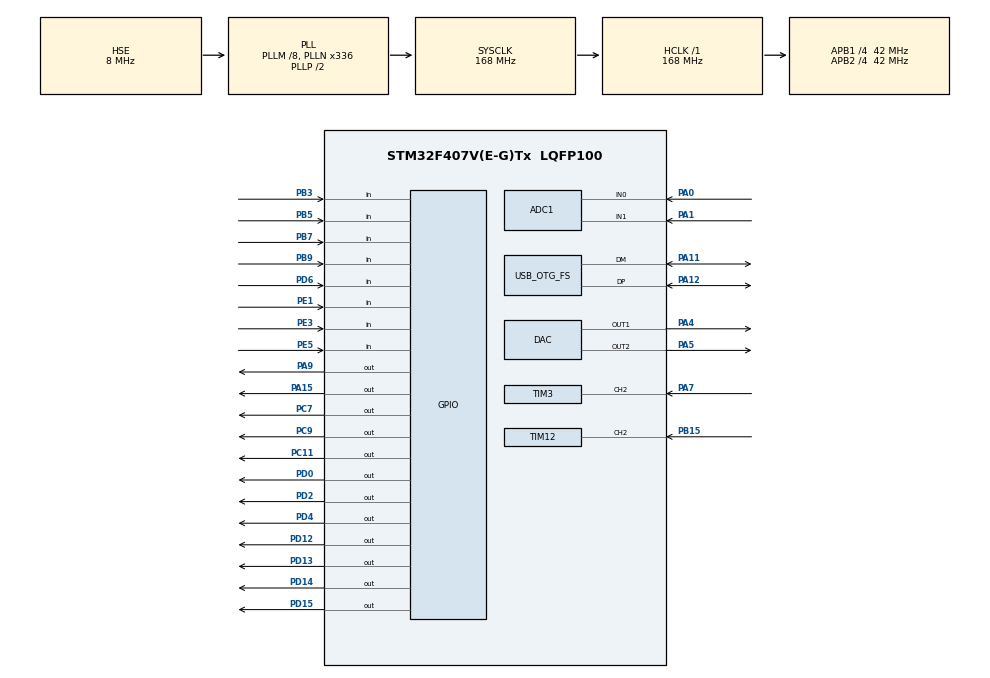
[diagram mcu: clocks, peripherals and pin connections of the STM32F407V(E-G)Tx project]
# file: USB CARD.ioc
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ADC1.AutoInjectedConv=DISABLE
ADC1.Channel-0\#ChannelRegularConversion=ADC_CHANNEL_0
ADC1.Channel-1\#ChannelRegularConversion=ADC_CHANNEL_1
ADC1.ContinuousConvMode=ENABLE
ADC1.DMAContinuousRequests=ENABLE
ADC1.EOCSelection=ADC_EOC_SEQ_CONV
ADC1.InjNumberOfConversion=0
ADC1.InjectedDiscontinuousConvMode=DISABLE
ADC1.NbrOfConversion=2
ADC1.NbrOfConversionFlag=1
ADC1.Rank-0\#ChannelRegularConversion=1
ADC1.Rank-1\#ChannelRegularConversion=2
ADC1.SamplingTime-0\#ChannelRegularConversion=ADC_SAMPLETIME_480CYCLES
ADC1.SamplingTime-1\#ChannelRegularConversion=ADC_SAMPLETIME_480CYCLES
ADC1.ScanConvMode=ENABLE
ADC1.master=1
DAC.DAC_Channel=DAC_CHANNEL_1
DAC.DAC_Channel2=DAC_CHANNEL_2
DAC.WaveGeneration=DISABLE
DAC.WaveGeneration2=DISABLE
Dma.ADC1.0.Direction=DMA_PERIPH_TO_MEMORY
Dma.ADC1.0.FIFOMode=DMA_FIFOMODE_DISABLE
Dma.ADC1.0.Instance=DMA2_Stream0
Dma.ADC1.0.MemDataAlignment=DMA_MDATAALIGN_HALFWORD
Dma.ADC1.0.MemInc=DMA_MINC_ENABLE
Dma.ADC1.0.Mode=DMA_CIRCULAR
Dma.ADC1.0.PeriphDataAlignment=DMA_PDATAALIGN_HALFWORD
Dma.ADC1.0.PeriphInc=DMA_PINC_DISABLE
Dma.ADC1.0.Priority=DMA_PRIORITY_LOW
Dma.Request0=ADC1
Mcu.Family=STM32F4
Mcu.Name=STM32F407V(E-G)Tx
Mcu.Package=LQFP100
NVIC.ADC_IRQn=true\:0\:0\:false\:false\:true
NVIC.DMA2_Stream0_IRQn=true\:0\:0\:false\:false\:true
NVIC.OTG_FS_IRQn=true\:0\:0\:false\:false\:true
NVIC.PriorityGroup=NVIC_PRIORITYGROUP_4
NVIC.TIM2_IRQn=true\:0\:0\:false\:false\:true
NVIC.TIM3_IRQn=true\:0\:0\:false\:false\:true
NVIC.TIM8_BRK_TIM12_IRQn=true\:0\:0\:false\:false\:true
PA0-WKUP.Signal=ADCx_IN0
PA1.Signal=ADCx_IN1
PA11.Mode=Device_Only
PA11.Signal=USB_OTG_FS_DM
PA12.Mode=Device_Only
PA12.Signal=USB_OTG_FS_DP
PA15.GPIO_ModeDefaultOutputPP=GPIO_MODE_OUTPUT_PP
PA15.GPIO_PuPd=GPIO_NOPULL
PA15.GPIO_Speed=GPIO_SPEED_FREQ_HIGH
PA15.PinState=GPIO_PIN_RESET
PA15.Signal=GPIO_Output
PA4.Signal=COMP_DAC1_group
PA5.Signal=COMP_DAC2_group
PA7.GPIO_PuPd=GPIO_PULLDOWN
PA7.GPIO_Speed=GPIO_SPEED_FREQ_HIGH
PA7.Signal=S_TIM3_CH2
PA9.GPIO_ModeDefaultOutputPP=GPIO_MODE_OUTPUT_PP
PA9.GPIO_PuPd=GPIO_NOPULL
PA9.GPIO_Speed=GPIO_SPEED_FREQ_HIGH
PA9.PinState=GPIO_PIN_RESET
PA9.Signal=GPIO_Output
PB15.GPIO_PuPd=GPIO_PULLDOWN
PB15.GPIO_Speed=GPIO_SPEED_FREQ_HIGH
PB15.Signal=S_TIM12_CH2
PB3.GPIO_Mode=GPIO_MODE_INPUT
PB3.GPIO_PuPd=GPIO_PULLUP
PB3.Signal=GPIO_Input
PB5.GPIO_Mode=GPIO_MODE_INPUT
PB5.GPIO_PuPd=GPIO_PULLUP
PB5.Signal=GPIO_Input
PB7.GPIO_Mode=GPIO_MODE_INPUT
PB7.GPIO_PuPd=GPIO_PULLUP
PB7.Signal=GPIO_Input
PB9.GPIO_Mode=GPIO_MODE_INPUT
PB9.GPIO_PuPd=GPIO_PULLUP
PB9.Signal=GPIO_Input
PC11.GPIO_ModeDefaultOutputPP=GPIO_MODE_OUTPUT_PP
PC11.GPIO_PuPd=GPIO_NOPULL
PC11.GPIO_Speed=GPIO_SPEED_FREQ_HIGH
PC11.PinState=GPIO_PIN_RESET
PC11.Signal=GPIO_Output
PC7.GPIO_ModeDefaultOutputPP=GPIO_MODE_OUTPUT_PP
PC7.GPIO_PuPd=GPIO_NOPULL
PC7.GPIO_Speed=GPIO_SPEED_FREQ_HIGH
PC7.PinState=GPIO_PIN_RESET
PC7.Signal=GPIO_Output
PC9.GPIO_ModeDefaultOutputPP=GPIO_MODE_OUTPUT_PP
PC9.GPIO_PuPd=GPIO_NOPULL
PC9.GPIO_Speed=GPIO_SPEED_FREQ_HIGH
PC9.PinState=GPIO_PIN_RESET
PC9.Signal=GPIO_Output
PD0.GPIO_ModeDefaultOutputPP=GPIO_MODE_OUTPUT_PP
PD0.GPIO_PuPd=GPIO_NOPULL
PD0.GPIO_Speed=GPIO_SPEED_FREQ_HIGH
PD0.PinState=GPIO_PIN_RESET
PD0.Signal=GPIO_Output
PD12.GPIO_ModeDefaultOutputPP=GPIO_MODE_OUTPUT_PP
PD12.GPIO_PuPd=GPIO_NOPULL
PD12.GPIO_Speed=GPIO_SPEED_FREQ_HIGH
PD12.PinState=GPIO_PIN_RESET
PD12.Signal=GPIO_Output
PD13.GPIO_ModeDefaultOutputPP=GPIO_MODE_OUTPUT_PP
PD13.GPIO_PuPd=GPIO_NOPULL
PD13.GPIO_Speed=GPIO_SPEED_FREQ_HIGH
PD13.PinState=GPIO_PIN_RESET
PD13.Signal=GPIO_Output
PD14.GPIO_ModeDefaultOutputPP=GPIO_MODE_OUTPUT_PP
PD14.GPIO_PuPd=GPIO_NOPULL
PD14.GPIO_Speed=GPIO_SPEED_FREQ_HIGH
PD14.PinState=GPIO_PIN_RESET
PD14.Signal=GPIO_Output
PD15.GPIO_ModeDefaultOutputPP=GPIO_MODE_OUTPUT_PP
PD15.GPIO_PuPd=GPIO_NOPULL
PD15.GPIO_Speed=GPIO_SPEED_FREQ_HIGH
PD15.PinState=GPIO_PIN_RESET
PD15.Signal=GPIO_Output
PD2.GPIO_ModeDefaultOutputPP=GPIO_MODE_OUTPUT_PP
PD2.GPIO_PuPd=GPIO_NOPULL
PD2.GPIO_Speed=GPIO_SPEED_FREQ_HIGH
PD2.PinState=GPIO_PIN_RESET
PD2.Signal=GPIO_Output
PD4.GPIO_ModeDefaultOutputPP=GPIO_MODE_OUTPUT_PP
PD4.GPIO_PuPd=GPIO_NOPULL
PD4.GPIO_Speed=GPIO_SPEED_FREQ_HIGH
PD4.PinState=GPIO_PIN_RESET
PD4.Signal=GPIO_Output
PD6.GPIO_Mode=GPIO_MODE_INPUT
PD6.GPIO_PuPd=GPIO_PULLUP
PD6.Signal=GPIO_Input
PE1.GPIO_Mode=GPIO_MODE_INPUT
PE1.GPIO_PuPd=GPIO_PULLUP
PE1.Signal=GPIO_Input
PE3.GPIO_Mode=GPIO_MODE_INPUT
PE3.GPIO_PuPd=GPIO_PULLUP
PE3.Signal=GPIO_Input
PE5.GPIO_Mode=GPIO_MODE_INPUT
PE5.GPIO_PuPd=GPIO_PULLUP
PE5.Signal=GPIO_Input
PH0-OSC_IN.Mode=HSE-External-Oscillator
PH0-OSC_IN.Signal=RCC_OSC_IN
PH1-OSC_OUT.Mode=HSE-External-Oscillator
PH1-OSC_OUT.Signal=RCC_OSC_OUT
ProjectManager.HeapSize=0x200
ProjectManager.StackSize=0x400
ProjectManager.TargetToolchain=MDK-ARM V5
RCC.48MHZClocksFreq_Value=48000000
RCC.AHBFreq_Value=168000000
RCC.APB1CLKDivider=RCC_HCLK_DIV4
RCC.APB1Freq_Value=42000000
RCC.APB1TimFreq_Value=84000000
RCC.APB2CLKDivider=RCC_HCLK_DIV4
RCC.APB2Freq_Value=42000000
RCC.APB2TimFreq_Value=84000000
RCC.ClockTypeHCLK=RCC_CLOCKTYPE_HCLK
RCC.ClockTypePCLK1=RCC_CLOCKTYPE_PCLK1
RCC.ClockTypePCLK2=RCC_CLOCKTYPE_PCLK2
RCC.ClockTypeSysClk=RCC_CLOCKTYPE_SYSCLK
RCC.CortexFreq_Value=168000000
RCC.EnableExtClockForI2S=false
RCC.EnableHSE=true
RCC.EnableHSERTCDevisor=false
RCC.EnableLSE=false
RCC.EnableLSERTC=false
RCC.ExtClockEnable=false
RCC.HCLKFreq_Value=168000000
RCC.HSEState=RCC_HSE_ON
RCC.HSE_VALUE=8000000
RCC.HSIState=RCC_HSI_OFF
RCC.HSI_VALUE=16000000
RCC.I2SEnable=false
RCC.IWDGEnable=false
RCC.LSE_VALUE=32768
RCC.LSIState=RCC_LSI_OFF
RCC.MCO1OutPutEnable=false
RCC.MCO2OutPutEnable=false
RCC.OscillatorTypeHSE=RCC_OSCILLATORTYPE_HSE
RCC.OscillatorTypeHSI=RCC_OSCILLATORTYPE_HSI
RCC.PLLM=8
RCC.PLLN=336
RCC.PLLQ=7
RCC.PLLSource=RCC_PLLSOURCE_HSE
RCC.PLLSourceVirtual=RCC_PLLSOURCE_HSE
RCC.PLLState=RCC_PLL_ON
RCC.RNGEnable=false
RCC.RTCEnable=false
RCC.SDIOEnable=false
RCC.SYSCLKFreq_VALUE=168000000
RCC.SYSCLKSource=RCC_SYSCLKSOURCE_PLLCLK
RCC.USBFSEnable=true
RCC.USBHSEnable=false
RCC.VCOOutputFreq_Value=336000000
SH.ADCx_IN0.0=ADC1_IN0,IN0
SH.ADCx_IN1.0=ADC1_IN1,IN1
SH.COMP_DAC1_group.0=DAC_OUT1,DAC_OUT1
SH.COMP_DAC2_group.0=DAC_OUT2,DAC_OUT2
SH.S_TIM12_CH2.0=TIM12_CH2,TriggerSource_TI2FP2
SH.S_TIM3_CH2.0=TIM3_CH2,TriggerSource_TI2FP2
TIM12.Period=65535
TIM12.Slave_TriggerFilter=15
TIM2.Period=499
TIM2.Prescaler=42000
TIM3.Period=65535
TIM3.Slave_TriggerFilter=15
USB_DEVICE.CLASS_NAME_FS=CUSTOMHID
USB_DEVICE.INTERFACE_STRING_CUSTOMHID_FS=USB Custom HID Interface
USB_DEVICE.MANUFACTURER_STRING-CUSTOM_HID_FS=DHBK - minht57
USB_DEVICE.PID_CUSTOMHID_FS=1996
USB_DEVICE.PRODUCT_STRING_CUSTOMHID_FS=USB CARD - minht57
USB_DEVICE.USBD_CUSTOMHID_OUTREPORT_BUF_SIZE-CUSTOM_HID_FS=64
USB_DEVICE.USBD_CUSTOM_HID_REPORT_DESC_SIZE-CUSTOM_HID_FS=64
USB_DEVICE.USBD_HandleTypeDef_FS=hUsbDevice_OTG_FS
USB_DEVICE.VID-CUSTOM_HID_FS=1010
USB_DEVICE.VirtualModeFS=Custom_Hid_FS
USB_OTG_FS.VirtualMode=Device_Only
USB_OTG_FS.dev_endpoints=4
USB_OTG_FS.phy_itface=PCD_PHY_EMBEDDED
VP_TIM12_VS_ControllerModeClock.Mode=Clock Mode
VP_TIM2_VS_ClockSourceINT.Mode=Internal
VP_TIM3_VS_ControllerModeClock.Mode=Clock Mode
VP_USB_DEVICE_VS_USB_DEVICE_CUSTOM_HID_FS.Mode=CUSTOM_HID_FS
board=USB CARD

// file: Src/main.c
/**
  ******************************************************************************
  * File Name          : main.c
  * Description        : Main program body
  ******************************************************************************
  *
  * Copyright (c) 2017 STMicroelectronics International N.V.
  * All rights reserved.
  *
  * Redistribution and use in source and binary forms, with or without
  * modification, are permitted, provided that the following conditions are met:
  *
  * 1. Redistribution of source code must retain the above copyright notice,
  *    this list of conditions and the following disclaimer.
  * 2. Redistributions in binary form must reproduce the above copyright notice,
  *    this list of conditions and the following disclaimer in the documentation
  *    and/or other materials provided with the distribution.
  * 3. Neither the name of STMicroelectronics nor the names of other
  *    contributors to this software may be used to endorse or promote products
  *    derived from this software without specific written permission.
  * 4. This software, including modifications and/or derivative works of this
  *    software, must execute solely and exclusively on microcontroller or
  *    microprocessor devices manufactured by or for STMicroelectronics.
  * 5. Redistribution and use of this software other than as permitted under
  *    this license is void and will automatically terminate your rights under
  *    this license.
  *
  * THIS SOFTWARE IS PROVIDED BY STMICROELECTRONICS AND CONTRIBUTORS "AS IS"
  * AND ANY EXPRESS, IMPLIED OR STATUTORY WARRANTIES, INCLUDING, BUT NOT
  * LIMITED TO, THE IMPLIED WARRANTIES OF MERCHANTABILITY, FITNESS FOR A
  * PARTICULAR PURPOSE AND NON-INFRINGEMENT OF THIRD PARTY INTELLECTUAL PROPERTY
  * RIGHTS ARE DISCLAIMED TO THE FULLEST EXTENT PERMITTED BY LAW. IN NO EVENT
  * SHALL STMICROELECTRONICS OR CONTRIBUTORS BE LIABLE FOR ANY DIRECT, INDIRECT,
  * INCIDENTAL, SPECIAL, EXEMPLARY, OR CONSEQUENTIAL DAMAGES (INCLUDING, BUT NOT
  * LIMITED TO, PROCUREMENT OF SUBSTITUTE GOODS OR SERVICES; LOSS OF USE, DATA,
  * OR PROFITS; OR BUSINESS INTERRUPTION) HOWEVER CAUSED AND ON ANY THEORY OF
  * LIABILITY, WHETHER IN CONTRACT, STRICT LIABILITY, OR TORT (INCLUDING
  * NEGLIGENCE OR OTHERWISE) ARISING IN ANY WAY OUT OF THE USE OF THIS SOFTWARE,
  * EVEN IF ADVISED OF THE POSSIBILITY OF SUCH DAMAGE.
  *
  ******************************************************************************
  */
#include "main.h"
#include "stm32f4xx_hal.h"
#include "usb_device.h"

ADC_HandleTypeDef hadc1;
DMA_HandleTypeDef hdma_adc1;

DAC_HandleTypeDef hdac;

TIM_HandleTypeDef htim2;
TIM_HandleTypeDef htim3;
TIM_HandleTypeDef htim12;

static uint16_t ui16ADC_Value[2];

void SystemClock_Config(void);
void Error_Handler(void);
static void MX_GPIO_Init(void);
static void MX_DMA_Init(void);
static void MX_DAC_Init(void);
static void MX_ADC1_Init(void);
static void MX_TIM12_Init(void);
static void MX_TIM2_Init(void);
static void MX_TIM3_Init(void);

int main(void)
{
  /* Reset of all peripherals, Initializes the Flash interface and the Systick. */
  HAL_Init();

  /* Configure the system clock */
  SystemClock_Config();

  /* Initialize all configured peripherals */
  MX_GPIO_Init();
  MX_DMA_Init();
  MX_USB_DEVICE_Init();
  MX_DAC_Init();
  MX_ADC1_Init();
  MX_TIM12_Init();
  MX_TIM2_Init();
  MX_TIM3_Init();

	HAL_ADC_Start_DMA(&hadc1, (uint32_t*) ui16ADC_Value, 2);
	HAL_DAC_Start(&hdac,DAC_CHANNEL_1);
	HAL_DAC_Start(&hdac,DAC_CHANNEL_2);

	HAL_TIM_Base_Start_IT(&htim3);
	HAL_TIM_Base_Start_IT(&htim12);
	HAL_TIM_Base_Start_IT(&htim2);

  while (1)
  {

  }
}

void ADC_Read_All(uint16_t* ui16Value){
	ui16Value[0] = ui16ADC_Value[0];
	ui16Value[1] = ui16ADC_Value[1];
}

void DAC_Write_Channel(uint16_t ui16Value, uint8_t ui8Channel){
	if(ui8Channel == 1){
		HAL_DAC_SetValue(&hdac,DAC_CHANNEL_1,DAC_ALIGN_12B_R,(uint32_t) ui16Value);
	}
	else if(ui8Channel == 2){
		HAL_DAC_SetValue(&hdac,DAC_CHANNEL_2,DAC_ALIGN_12B_R,(uint32_t) ui16Value);
	}
}

void Counter_Read_All(uint16_t* ui16Value){
	ui16Value[0] = __HAL_TIM_GET_COUNTER(&htim3);
	ui16Value[1] = __HAL_TIM_GET_COUNTER(&htim12);
}

void Counter_Reset(uint8_t ui8Channel){
	if(ui8Channel == 0){
		__HAL_TIM_SET_COUNTER(&htim3,0);
	}
	else if(ui8Channel == 1){
		__HAL_TIM_SET_COUNTER(&htim12,0);
	}
}

/** System Clock Configuration
*/
void SystemClock_Config(void)
{

  RCC_OscInitTypeDef RCC_OscInitStruct;
  RCC_ClkInitTypeDef RCC_ClkInitStruct;

    /**Configure the main internal regulator output voltage
    */
  __HAL_RCC_PWR_CLK_ENABLE();

  __HAL_PWR_VOLTAGESCALING_CONFIG(PWR_REGULATOR_VOLTAGE_SCALE1);

    /**Initializes the CPU, AHB and APB busses clocks
    */
  RCC_OscInitStruct.OscillatorType = RCC_OSCILLATORTYPE_HSE;
  RCC_OscInitStruct.HSEState = RCC_HSE_ON;
  RCC_OscInitStruct.PLL.PLLState = RCC_PLL_ON;
  RCC_OscInitStruct.PLL.PLLSource = RCC_PLLSOURCE_HSE;
  RCC_OscInitStruct.PLL.PLLM = 8;
  RCC_OscInitStruct.PLL.PLLN = 336;
  RCC_OscInitStruct.PLL.PLLP = RCC_PLLP_DIV2;
  RCC_OscInitStruct.PLL.PLLQ = 7;
  if (HAL_RCC_OscConfig(&RCC_OscInitStruct) != HAL_OK)
  {
    Error_Handler();
  }

    /**Initializes the CPU, AHB and APB busses clocks
    */
  RCC_ClkInitStruct.ClockType = RCC_CLOCKTYPE_HCLK|RCC_CLOCKTYPE_SYSCLK
                              |RCC_CLOCKTYPE_PCLK1|RCC_CLOCKTYPE_PCLK2;
  RCC_ClkInitStruct.SYSCLKSource = RCC_SYSCLKSOURCE_PLLCLK;
  RCC_ClkInitStruct.AHBCLKDivider = RCC_SYSCLK_DIV1;
  RCC_ClkInitStruct.APB1CLKDivider = RCC_HCLK_DIV4;
  RCC_ClkInitStruct.APB2CLKDivider = RCC_HCLK_DIV4;

  if (HAL_RCC_ClockConfig(&RCC_ClkInitStruct, FLASH_LATENCY_5) != HAL_OK)
  {
    Error_Handler();
  }

    /**Configure the Systick interrupt time
    */
  HAL_SYSTICK_Config(HAL_RCC_GetHCLKFreq()/1000);

    /**Configure the Systick
    */
  HAL_SYSTICK_CLKSourceConfig(SYSTICK_CLKSOURCE_HCLK);

  /* SysTick_IRQn interrupt configuration */
  HAL_NVIC_SetPriority(SysTick_IRQn, 0, 0);
}

/* ADC1 init function */
static void MX_ADC1_Init(void)
{

  ADC_ChannelConfTypeDef sConfig;

    /**Configure the global features of the ADC (Clock, Resolution, Data Alignment and number of conversion)
    */
  hadc1.Instance = ADC1;
  hadc1.Init.ClockPrescaler = ADC_CLOCK_SYNC_PCLK_DIV2;
  hadc1.Init.Resolution = ADC_RESOLUTION_12B;
  hadc1.Init.ScanConvMode = ENABLE;
  hadc1.Init.ContinuousConvMode = ENABLE;
  hadc1.Init.DiscontinuousConvMode = DISABLE;
  hadc1.Init.ExternalTrigConvEdge = ADC_EXTERNALTRIGCONVEDGE_NONE;
  hadc1.Init.ExternalTrigConv = ADC_SOFTWARE_START;
  hadc1.Init.DataAlign = ADC_DATAALIGN_RIGHT;
  hadc1.Init.NbrOfConversion = 2;
  hadc1.Init.DMAContinuousRequests = ENABLE;
  hadc1.Init.EOCSelection = ADC_EOC_SEQ_CONV;
  if (HAL_ADC_Init(&hadc1) != HAL_OK)
  {
    Error_Handler();
  }

    /**Configure for the selected ADC regular channel its corresponding rank in the sequencer and its sample time.
    */
  sConfig.Channel = ADC_CHANNEL_0;
  sConfig.Rank = 1;
  sConfig.SamplingTime = ADC_SAMPLETIME_480CYCLES;
  if (HAL_ADC_ConfigChannel(&hadc1, &sConfig) != HAL_OK)
  {
    Error_Handler();
  }

    /**Configure for the selected ADC regular channel its corresponding rank in the sequencer and its sample time.
    */
  sConfig.Channel = ADC_CHANNEL_1;
  sConfig.Rank = 2;
  if (HAL_ADC_ConfigChannel(&hadc1, &sConfig) != HAL_OK)
  {
    Error_Handler();
  }

}

/* DAC init function */
static void MX_DAC_Init(void)
{

  DAC_ChannelConfTypeDef sConfig;

    /**DAC Initialization
    */
  hdac.Instance = DAC;
  if (HAL_DAC_Init(&hdac) != HAL_OK)
  {
    Error_Handler();
  }

    /**DAC channel OUT1 config
    */
  sConfig.DAC_Trigger = DAC_TRIGGER_NONE;
  sConfig.DAC_OutputBuffer = DAC_OUTPUTBUFFER_ENABLE;
  if (HAL_DAC_ConfigChannel(&hdac, &sConfig, DAC_CHANNEL_1) != HAL_OK)
  {
    Error_Handler();
  }

    /**DAC channel OUT2 config
    */
  if (HAL_DAC_ConfigChannel(&hdac, &sConfig, DAC_CHANNEL_2) != HAL_OK)
  {
    Error_Handler();
  }

}

/* TIM2 init function */
static void MX_TIM2_Init(void)
{

  TIM_ClockConfigTypeDef sClockSourceConfig;
  TIM_MasterConfigTypeDef sMasterConfig;

  htim2.Instance = TIM2;
  htim2.Init.Prescaler = 42000;
  htim2.Init.CounterMode = TIM_COUNTERMODE_UP;
  htim2.Init.Period = 299;
  htim2.Init.ClockDivision = TIM_CLOCKDIVISION_DIV1;
  if (HAL_TIM_Base_Init(&htim2) != HAL_OK)
  {
    Error_Handler();
  }

  sClockSourceConfig.ClockSource = TIM_CLOCKSOURCE_INTERNAL;
  if (HAL_TIM_ConfigClockSource(&htim2, &sClockSourceConfig) != HAL_OK)
  {
    Error_Handler();
  }

  sMasterConfig.MasterOutputTrigger = TIM_TRGO_RESET;
  sMasterConfig.MasterSlaveMode = TIM_MASTERSLAVEMODE_DISABLE;
  if (HAL_TIMEx_MasterConfigSynchronization(&htim2, &sMasterConfig) != HAL_OK)
  {
    Error_Handler();
  }

}

/* TIM3 init function */
static void MX_TIM3_Init(void)
{

  TIM_SlaveConfigTypeDef sSlaveConfig;
  TIM_MasterConfigTypeDef sMasterConfig;

  htim3.Instance = TIM3;
  htim3.Init.Prescaler = 0;
  htim3.Init.CounterMode = TIM_COUNTERMODE_UP;
  htim3.Init.Period = 65535;
  htim3.Init.ClockDivision = TIM_CLOCKDIVISION_DIV1;
  if (HAL_TIM_Base_Init(&htim3) != HAL_OK)
  {
    Error_Handler();
  }

  sSlaveConfig.SlaveMode = TIM_SLAVEMODE_EXTERNAL1;
  sSlaveConfig.InputTrigger = TIM_TS_TI2FP2;
  sSlaveConfig.TriggerPolarity = TIM_TRIGGERPOLARITY_RISING;
  sSlaveConfig.TriggerFilter = 15;
  if (HAL_TIM_SlaveConfigSynchronization(&htim3, &sSlaveConfig) != HAL_OK)
  {
    Error_Handler();
  }

  sMasterConfig.MasterOutputTrigger = TIM_TRGO_RESET;
  sMasterConfig.MasterSlaveMode = TIM_MASTERSLAVEMODE_DISABLE;
  if (HAL_TIMEx_MasterConfigSynchronization(&htim3, &sMasterConfig) != HAL_OK)
  {
    Error_Handler();
  }

}

/* TIM12 init function */
static void MX_TIM12_Init(void)
{

  TIM_SlaveConfigTypeDef sSlaveConfig;

  htim12.Instance = TIM12;
  htim12.Init.Prescaler = 0;
  htim12.Init.CounterMode = TIM_COUNTERMODE_UP;
  htim12.Init.Period = 65535;
  htim12.Init.ClockDivision = TIM_CLOCKDIVISION_DIV1;
  if (HAL_TIM_Base_Init(&htim12) != HAL_OK)
  {
    Error_Handler();
  }

  sSlaveConfig.SlaveMode = TIM_SLAVEMODE_EXTERNAL1;
  sSlaveConfig.InputTrigger = TIM_TS_TI2FP2;
  sSlaveConfig.TriggerPolarity = TIM_TRIGGERPOLARITY_RISING;
  sSlaveConfig.TriggerFilter = 15;
  if (HAL_TIM_SlaveConfigSynchronization(&htim12, &sSlaveConfig) != HAL_OK)
  {
    Error_Handler();
  }

}

static void MX_DMA_Init(void)
{
  /* DMA controller clock enable */
  __HAL_RCC_DMA2_CLK_ENABLE();

  /* DMA interrupt init */
  /* DMA2_Stream0_IRQn interrupt configuration */
  HAL_NVIC_SetPriority(DMA2_Stream0_IRQn, 0, 0);
  HAL_NVIC_EnableIRQ(DMA2_Stream0_IRQn);

}

/** Configure pins as
        * Analog
        * Input
        * Output
        * EVENT_OUT
        * EXTI
*/
static void MX_GPIO_Init(void)
{

  GPIO_InitTypeDef GPIO_InitStruct;

  /* GPIO Ports Clock Enable */
  __HAL_RCC_GPIOE_CLK_ENABLE();
  __HAL_RCC_GPIOH_CLK_ENABLE();
  __HAL_RCC_GPIOA_CLK_ENABLE();
  __HAL_RCC_GPIOB_CLK_ENABLE();
  __HAL_RCC_GPIOD_CLK_ENABLE();
  __HAL_RCC_GPIOC_CLK_ENABLE();

  /*Configure GPIO pin Output Level */
  HAL_GPIO_WritePin(GPIOD, GPIO_PIN_12|GPIO_PIN_13|GPIO_PIN_14|GPIO_PIN_15
                          |GPIO_PIN_0|GPIO_PIN_2|GPIO_PIN_4, GPIO_PIN_RESET);

  /*Configure GPIO pin Output Level */
  HAL_GPIO_WritePin(GPIOC, GPIO_PIN_7|GPIO_PIN_9|GPIO_PIN_11, GPIO_PIN_RESET);

  /*Configure GPIO pin Output Level */
  HAL_GPIO_WritePin(GPIOA, GPIO_PIN_9|GPIO_PIN_15, GPIO_PIN_RESET);

  /*Configure GPIO pins : PE3 PE5 PE1 */
  GPIO_InitStruct.Pin = GPIO_PIN_3|GPIO_PIN_5|GPIO_PIN_1;
  GPIO_InitStruct.Mode = GPIO_MODE_INPUT;
  GPIO_InitStruct.Pull = GPIO_PULLUP;
  HAL_GPIO_Init(GPIOE, &GPIO_InitStruct);

  /*Configure GPIO pins : PD12 PD13 PD14 PD15
                           PD0 PD2 PD4 */
  GPIO_InitStruct.Pin = GPIO_PIN_12|GPIO_PIN_13|GPIO_PIN_14|GPIO_PIN_15
                          |GPIO_PIN_0|GPIO_PIN_2|GPIO_PIN_4;
  GPIO_InitStruct.Mode = GPIO_MODE_OUTPUT_PP;
  GPIO_InitStruct.Pull = GPIO_NOPULL;
  GPIO_InitStruct.Speed = GPIO_SPEED_FREQ_HIGH;
  HAL_GPIO_Init(GPIOD, &GPIO_InitStruct);

  /*Configure GPIO pins : PC7 PC9 PC11 */
  GPIO_InitStruct.Pin = GPIO_PIN_7|GPIO_PIN_9|GPIO_PIN_11;
  GPIO_InitStruct.Mode = GPIO_MODE_OUTPUT_PP;
  GPIO_InitStruct.Pull = GPIO_NOPULL;
  GPIO_InitStruct.Speed = GPIO_SPEED_FREQ_HIGH;
  HAL_GPIO_Init(GPIOC, &GPIO_InitStruct);

  /*Configure GPIO pins : PA9 PA15 */
  GPIO_InitStruct.Pin = GPIO_PIN_9|GPIO_PIN_15;
  GPIO_InitStruct.Mode = GPIO_MODE_OUTPUT_PP;
  GPIO_InitStruct.Pull = GPIO_NOPULL;
  GPIO_InitStruct.Speed = GPIO_SPEED_FREQ_HIGH;
  HAL_GPIO_Init(GPIOA, &GPIO_InitStruct);

  /*Configure GPIO pin : PD6 */
  GPIO_InitStruct.Pin = GPIO_PIN_6;
  GPIO_InitStruct.Mode = GPIO_MODE_INPUT;
  GPIO_InitStruct.Pull = GPIO_PULLUP;
  HAL_GPIO_Init(GPIOD, &GPIO_InitStruct);

  /*Configure GPIO pins : PB3 PB5 PB7 PB9 */
  GPIO_InitStruct.Pin = GPIO_PIN_3|GPIO_PIN_5|GPIO_PIN_7|GPIO_PIN_9;
  GPIO_InitStruct.Mode = GPIO_MODE_INPUT;
  GPIO_InitStruct.Pull = GPIO_PULLUP;
  HAL_GPIO_Init(GPIOB, &GPIO_InitStruct);

}

void Error_Handler(void)
{
  /* USER CODE BEGIN Error_Handler */
  /* User can add his own implementation to report the HAL error return state */
  while(1)
  {
		HAL_GPIO_TogglePin(GPIOD,GPIO_PIN_12);
  }
  /* USER CODE END Error_Handler */
}

/************************ (C) COPYRIGHT STMicroelectronics *****END OF FILE****/
